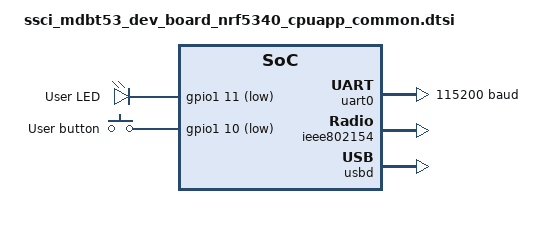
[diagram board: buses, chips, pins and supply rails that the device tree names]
#include "ssci_mdbt53_dev_board-pinctrl.dtsi"
#include <zephyr/dt-bindings/gpio/gpio.h>

/ {
	chosen {
		zephyr,console = &uart0;
		zephyr,shell-uart = &uart0;
		zephyr,uart-mcumgr = &uart0;
		zephyr,bt-mon-uart = &uart0;
		zephyr,bt-c2h-uart = &uart0;
		zephyr,bt-hci = &bt_hci_ipc0;
		nordic,802154-spinel-ipc = &ipc0;
		zephyr,ieee802154 = &ieee802154;
	};

	leds {
		compatible = "gpio-leds";

		led0: led_0 {
			gpios = <&gpio1 11 GPIO_ACTIVE_LOW>;
			label = "User LED";
		};
	};

	buttons {
		compatible = "gpio-keys";

		button0: button_0 {
			gpios = <&gpio1 10 (GPIO_PULL_UP | GPIO_ACTIVE_LOW)>;
			label = "User button";
		};
	};

	aliases {
		led0 = &led0;
		sw0 = &button0;
		mcuboot-button0 = &button0;
		mcuboot-led0 = &led0;
		watchdog0 = &wdt0;
	};
};

&gpiote {
	status = "okay";
};

&gpio0 {
	status = "okay";
};

&gpio1 {
	status = "okay";
};

&uart0 {
	status = "okay";
	current-speed = <115200>;
	pinctrl-0 = <&uart0_default>;
	pinctrl-1 = <&uart0_sleep>;
	pinctrl-names = "default", "sleep";
};

&ieee802154 {
	status = "okay";
};

zephyr_udc0: &usbd {
	compatible = "nordic,nrf-usbd";
	status = "okay";
};
